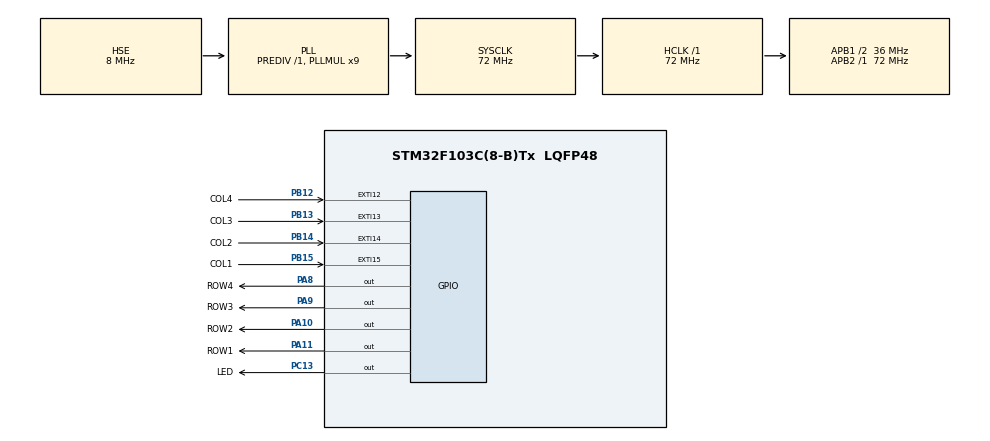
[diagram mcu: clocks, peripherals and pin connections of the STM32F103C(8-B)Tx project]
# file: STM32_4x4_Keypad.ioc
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Mcu.Family=STM32F1
Mcu.Name=STM32F103C(8-B)Tx
Mcu.Package=LQFP48
NVIC.EXTI15_10_IRQn=true\:0\:0\:false\:false\:false\:true\:false
NVIC.PriorityGroup=NVIC_PRIORITYGROUP_4
PA10.GPIO_Label=ROW2
PA10.GPIO_Speed=GPIO_SPEED_FREQ_MEDIUM
PA10.PinState=GPIO_PIN_RESET
PA10.Signal=GPIO_Output
PA11.GPIO_Label=ROW1
PA11.GPIO_Speed=GPIO_SPEED_FREQ_MEDIUM
PA11.PinState=GPIO_PIN_RESET
PA11.Signal=GPIO_Output
PA13.Mode=Serial_Wire
PA13.Signal=SYS_JTMS-SWDIO
PA14.Mode=Serial_Wire
PA14.Signal=SYS_JTCK-SWCLK
PA8.GPIO_Label=ROW4
PA8.GPIO_Speed=GPIO_SPEED_FREQ_MEDIUM
PA8.PinState=GPIO_PIN_RESET
PA8.Signal=GPIO_Output
PA9.GPIO_Label=ROW3
PA9.GPIO_Speed=GPIO_SPEED_FREQ_MEDIUM
PA9.PinState=GPIO_PIN_RESET
PA9.Signal=GPIO_Output
PB12.GPIO_Label=COL4
PB12.GPIO_ModeDefaultEXTI=GPIO_MODE_IT_RISING
PB12.GPIO_PuPd=GPIO_PULLDOWN
PB12.Signal=GPXTI12
PB13.GPIO_Label=COL3
PB13.GPIO_ModeDefaultEXTI=GPIO_MODE_IT_RISING
PB13.GPIO_PuPd=GPIO_PULLDOWN
PB13.Signal=GPXTI13
PB14.GPIO_Label=COL2
PB14.GPIO_ModeDefaultEXTI=GPIO_MODE_IT_RISING
PB14.GPIO_PuPd=GPIO_PULLDOWN
PB14.Signal=GPXTI14
PB15.GPIO_Label=COL1
PB15.GPIO_ModeDefaultEXTI=GPIO_MODE_IT_RISING
PB15.GPIO_PuPd=GPIO_PULLDOWN
PB15.Signal=GPXTI15
PC13-TAMPER-RTC.GPIO_Label=LED
PC13-TAMPER-RTC.GPIO_Speed=GPIO_SPEED_FREQ_MEDIUM
PC13-TAMPER-RTC.PinState=GPIO_PIN_SET
PC13-TAMPER-RTC.Signal=GPIO_Output
PD0-OSC_IN.Mode=HSE-External-Oscillator
PD0-OSC_IN.Signal=RCC_OSC_IN
PD1-OSC_OUT.Mode=HSE-External-Oscillator
PD1-OSC_OUT.Signal=RCC_OSC_OUT
ProjectManager.HeapSize=0x200
ProjectManager.StackSize=0x400
ProjectManager.TargetToolchain=STM32CubeIDE
RCC.AHBFreq_Value=72000000
RCC.APB1CLKDivider=RCC_HCLK_DIV2
RCC.APB1Freq_Value=36000000
RCC.APB1TimFreq_Value=72000000
RCC.APB2Freq_Value=72000000
RCC.APB2TimFreq_Value=72000000
RCC.HCLKFreq_Value=72000000
RCC.PLLMUL=RCC_PLL_MUL9
RCC.PLLSourceVirtual=RCC_PLLSOURCE_HSE
RCC.SYSCLKFreq_VALUE=72000000
RCC.SYSCLKSource=RCC_SYSCLKSOURCE_PLLCLK
RCC.USBFreq_Value=72000000
board=custom

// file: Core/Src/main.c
/* USER CODE BEGIN Header */
/**
  ******************************************************************************
  * @file           : main.c
  * @brief          : Main program body
  ******************************************************************************
  * @attention
  *
  * <h2><center>&copy; Copyright (c) 2020 STMicroelectronics.
  * All rights reserved.</center></h2>
  *
  * This software component is licensed by ST under BSD 3-Clause license,
  * the "License"; You may not use this file except in compliance with the
  * License. You may obtain a copy of the License at:
  *                        opensource.org/licenses/BSD-3-Clause
  *
  ******************************************************************************
  */
/* USER CODE END Header */
#include "main.h"

/* USER CODE BEGIN Includes */

#include "keypad.h"
#include "keypad_gpio.h"

/* USER CODE END Includes */

/* USER CODE BEGIN PV */

KeypadTypeDef keypad;

/* USER CODE END PV */

void SystemClock_Config(void);
static void MX_GPIO_Init(void);

int main(void)
{

  /* MCU Configuration--------------------------------------------------------*/

  /* Reset of all peripherals, Initializes the Flash interface and the Systick. */
  HAL_Init();

  /* Configure the system clock */
  SystemClock_Config();

  /* Initialize all configured peripherals */
  MX_GPIO_Init();
  /* USER CODE BEGIN 2 */

  keypad_init(ColumnPort, ColumnPin, RowPort, RowPin);

  /* USER CODE END 2 */

  /* Infinite loop */
  while (1)
  {

  }
}

void SystemClock_Config(void)
{
  RCC_OscInitTypeDef RCC_OscInitStruct = {0};
  RCC_ClkInitTypeDef RCC_ClkInitStruct = {0};

  /** Initializes the RCC Oscillators according to the specified parameters
  * in the RCC_OscInitTypeDef structure.
  */
  RCC_OscInitStruct.OscillatorType = RCC_OSCILLATORTYPE_HSE;
  RCC_OscInitStruct.HSEState = RCC_HSE_ON;
  RCC_OscInitStruct.HSEPredivValue = RCC_HSE_PREDIV_DIV1;
  RCC_OscInitStruct.HSIState = RCC_HSI_ON;
  RCC_OscInitStruct.PLL.PLLState = RCC_PLL_ON;
  RCC_OscInitStruct.PLL.PLLSource = RCC_PLLSOURCE_HSE;
  RCC_OscInitStruct.PLL.PLLMUL = RCC_PLL_MUL9;
  if (HAL_RCC_OscConfig(&RCC_OscInitStruct) != HAL_OK)
  {
    Error_Handler();
  }
  /** Initializes the CPU, AHB and APB buses clocks
  */
  RCC_ClkInitStruct.ClockType = RCC_CLOCKTYPE_HCLK|RCC_CLOCKTYPE_SYSCLK
                              |RCC_CLOCKTYPE_PCLK1|RCC_CLOCKTYPE_PCLK2;
  RCC_ClkInitStruct.SYSCLKSource = RCC_SYSCLKSOURCE_PLLCLK;
  RCC_ClkInitStruct.AHBCLKDivider = RCC_SYSCLK_DIV1;
  RCC_ClkInitStruct.APB1CLKDivider = RCC_HCLK_DIV2;
  RCC_ClkInitStruct.APB2CLKDivider = RCC_HCLK_DIV1;

  if (HAL_RCC_ClockConfig(&RCC_ClkInitStruct, FLASH_LATENCY_2) != HAL_OK)
  {
    Error_Handler();
  }
}

static void MX_GPIO_Init(void)
{
  GPIO_InitTypeDef GPIO_InitStruct = {0};

  /* GPIO Ports Clock Enable */
  __HAL_RCC_GPIOC_CLK_ENABLE();
  __HAL_RCC_GPIOD_CLK_ENABLE();
  __HAL_RCC_GPIOB_CLK_ENABLE();
  __HAL_RCC_GPIOA_CLK_ENABLE();

  /*Configure GPIO pin Output Level */
  HAL_GPIO_WritePin(LED_GPIO_Port, LED_Pin, GPIO_PIN_SET);

  /*Configure GPIO pin Output Level */
  HAL_GPIO_WritePin(GPIOA, ROW4_Pin|ROW3_Pin|ROW2_Pin|ROW1_Pin, GPIO_PIN_RESET);

  /*Configure GPIO pin : LED_Pin */
  GPIO_InitStruct.Pin = LED_Pin;
  GPIO_InitStruct.Mode = GPIO_MODE_OUTPUT_PP;
  GPIO_InitStruct.Pull = GPIO_NOPULL;
  GPIO_InitStruct.Speed = GPIO_SPEED_FREQ_MEDIUM;
  HAL_GPIO_Init(LED_GPIO_Port, &GPIO_InitStruct);

  /*Configure GPIO pins : COL4_Pin COL3_Pin COL2_Pin COL1_Pin */
  GPIO_InitStruct.Pin = COL4_Pin|COL3_Pin|COL2_Pin|COL1_Pin;
  GPIO_InitStruct.Mode = GPIO_MODE_IT_RISING;
  GPIO_InitStruct.Pull = GPIO_PULLDOWN;
  HAL_GPIO_Init(GPIOB, &GPIO_InitStruct);

  /*Configure GPIO pins : ROW4_Pin ROW3_Pin ROW2_Pin ROW1_Pin */
  GPIO_InitStruct.Pin = ROW4_Pin|ROW3_Pin|ROW2_Pin|ROW1_Pin;
  GPIO_InitStruct.Mode = GPIO_MODE_OUTPUT_PP;
  GPIO_InitStruct.Pull = GPIO_NOPULL;
  GPIO_InitStruct.Speed = GPIO_SPEED_FREQ_MEDIUM;
  HAL_GPIO_Init(GPIOA, &GPIO_InitStruct);

  /* EXTI interrupt init*/
  HAL_NVIC_SetPriority(EXTI15_10_IRQn, 0, 0);
  HAL_NVIC_EnableIRQ(EXTI15_10_IRQn);

}

void Error_Handler(void)
{
}

/************************ (C) COPYRIGHT STMicroelectronics *****END OF FILE****/
